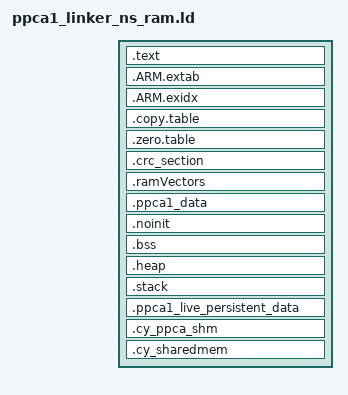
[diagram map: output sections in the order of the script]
/***************************************************************************//**
* \file psc3_p8_ppca1_ns_ram.ld
* \version 1.0.0
*
* Linker file for the GNU C compiler.
*
* The main purpose of the linker script is to describe how the sections in the
* input files should be mapped into the output file, and to control the memory
* layout of the output file.
*
* \note The entry point location is fixed and starts at 0x10000000. The valid
* application image should be placed there.
*
* \note The linker files included with the PDL template projects must be generic
* and handle all common use cases. Your project may not use every section
* defined in the linker files. In that case you may see warnings during the
* build process. In your project, you can simply comment out or remove the
* relevant code in the linker file.
*
********************************************************************************
* \copyright
* Copyright 2024 Cypress Semiconductor Corporation
* SPDX-License-Identifier: Apache-2.0
*
* Licensed under the Apache License, Version 2.0 (the "License");
* you may not use this file except in compliance with the License.
* You may obtain a copy of the License at
*
*     http://www.apache.org/licenses/LICENSE-2.0
*
* Unless required by applicable law or agreed to in writing, software
* distributed under the License is distributed on an "AS IS" BASIS,
* WITHOUT WARRANTIES OR CONDITIONS OF ANY KIND, either express or implied.
* See the License for the specific language governing permissions and
* limitations under the License.
*******************************************************************************/

OUTPUT_FORMAT ("elf32-littlearm", "elf32-bigarm", "elf32-littlearm")
SEARCH_DIR(.)
GROUP(-lgcc -lc -lnosys )
GROUP(libgcc.a libc.a libm.a libnosys.a)
ENTRY(Reset_Handler)

/* The size of the stack section at the end of CM33 SRAM */
RAMVECTORS_ALIGNMENT        = 512;
STACK_SIZE = 0x800; /* 2K for stack */


/* Force symbol to be entered in the output file as an undefined symbol. Doing
* this may, for example, trigger linking of additional modules from standard
* libraries. You may list several symbols for each EXTERN, and you may use
* EXTERN multiple times. This command has the same effect as the -u command-line
* option.
*/
EXTERN(Reset_Handler)

/* Include the device memory definitions generated by the Device Configurator */
INCLUDE cymem_gnu_CM33_2.ld

/* Select active PPCA1 slot using BUILD_NUM parity.
 * Even BUILD_NUM -> slot A, odd BUILD_NUM -> slot B.
 */
BUILD_NUM = DEFINED(BUILD_NUM) ? BUILD_NUM : 0;
ppca1_code_start = ((BUILD_NUM % 2) == 0) ? ORIGIN(ppca1_code_A) : ORIGIN(ppca1_code_B);
ppca1_crc_start  = ((BUILD_NUM % 2) == 0) ? ORIGIN(ppca1_crc_A) : ORIGIN(ppca1_crc_B);
ppca1_code_size  = ((BUILD_NUM % 2) == 0) ? LENGTH(ppca1_code_A) : LENGTH(ppca1_code_B);
ppca1_crc_size   = ((BUILD_NUM % 2) == 0) ? LENGTH(ppca1_crc_A) : LENGTH(ppca1_crc_B);

/* Library configurations */
GROUP(libgcc.a libc.a libm.a libnosys.a)

/* Linker script to place sections and symbol values. Should be used together
 * with other linker script that defines memory regions FLASH and RAM.
 * It references following symbols, which must be defined in code:
 *   Reset_Handler : Entry of reset handler
 *
 * It defines following symbols, which code can use without definition:
 *   __exidx_start
 *   __exidx_end
 *   __copy_table_start__
 *   __copy_table_end__
 *   __zero_table_start__
 *   __zero_table_end__
 *   __etext
 *   __data_start__
 *   __preinit_array_start
 *   __preinit_array_end
 *   __init_array_start
 *   __init_array_end
 *   __fini_array_start
 *   __fini_array_end
 *   __data_end__
 *   __bss_start__
 *   __bss_end__
 *   __end__
 *   end
 *   __HeapLimit
 *   __StackLimit
 *   __StackTop
 *   __stack
 *   __Vectors_End
 *   __Vectors_Size
 */


SECTIONS
{
    /* Cortex-M33 application flash area */
    .text ppca1_code_start : AT(ppca1_code_start)
    {
        /* Cortex-M33 flash vector table */
        . = ALIGN(4);
        __Vectors = . ;
        KEEP(*(.vectors))
        . = ALIGN(4);
        __Vectors_End = .;
        __Vectors_Size = __Vectors_End - __Vectors;
        __end__ = .;

        . = ALIGN(4);
        *(.text*)

        KEEP(*(.init))
        KEEP(*(.fini))

        /* .ctors */
        *crtbegin.o(.ctors)
        *crtbegin?.o(.ctors)
        *(EXCLUDE_FILE(*crtend?.o *crtend.o) .ctors)
        *(SORT(.ctors.*))
        *(.ctors)

        /* .dtors */
        *crtbegin.o(.dtors)
        *crtbegin?.o(.dtors)
        *(EXCLUDE_FILE(*crtend?.o *crtend.o) .dtors)
        *(SORT(.dtors.*))
        *(.dtors)

        /* Read-only code (constants). */
        *(.rodata .rodata.* .constdata .constdata.* .conststring .conststring.*)

        KEEP(*(.eh_frame*))
    }


    .ARM.extab :
    {
        *(.ARM.extab* .gnu.linkonce.armextab.*)
    }

    __exidx_start = .;

    .ARM.exidx :
    {
        *(.ARM.exidx* .gnu.linkonce.armexidx.*)
    }
    __exidx_end = .;


    /* copy code-RAM to data-RAM */
    .copy.table :
    {
        . = ALIGN(4);
        __copy_table_start__ = .;

        /* Note: The interrupt vector table is NOT copied to data SRAM.
         * For PPCA cores the application executes directly from code SRAM,
         * so the vector table is used in-place at the image base. This avoids
         * the vector copy on every (cold and live) boot and keeps the live
         * update app switch fast. The VTOR is set to the image base directly. */

        /* Copy data section from code-RAM to data-RAM */
        LONG (__etext)                                      /* From */
        LONG (__data_start__)                               /* To   */
        LONG ((__data_end__ - __data_start__)/4)            /* Size */

        __copy_table_end__ = .;
    }


    /* Mark bss sections */
    .zero.table :
    {
        . = ALIGN(4);
        __zero_table_start__ = .;
        LONG (__bss_start__)
        LONG ((__bss_end__ - __bss_start__)/4)
        __zero_table_end__ = .;
    }

    __etext =  . ;

    ASSERT(__etext <= (ppca1_code_start + ppca1_code_size), "region ppca1_code overflowed")

    /* Define symbols for the start and end of the CRC calculation range */
    __crc_start__ = ppca1_code_start;
    __crc_end__   = ppca1_crc_start;
    
    .crc_section ppca1_crc_start :
    {
        . = ALIGN(4);
        KEEP(*(.crc_section))
    }

    .ramVectors (NOLOAD) : /*ALIGN(8)*/
    {
        . = ALIGN(RAMVECTORS_ALIGNMENT);
        __ram_vectors_start__ = .;
        KEEP(*(.ram_vectors))
        __ram_vectors_end__   = .;
    } > ppca1_data

    .ppca1_data : AT (__etext)
    {
        __data_start__ = .;

        . = ALIGN(4);
        *(.data*)

        . = ALIGN(4);
        /* preinit data */
        PROVIDE_HIDDEN (__preinit_array_start = .);
        KEEP(*(.preinit_array))
        PROVIDE_HIDDEN (__preinit_array_end = .);

        . = ALIGN(4);
        /* init data */
        PROVIDE_HIDDEN (__init_array_start = .);
        KEEP(*(SORT(.init_array.*)))
        KEEP(*(.init_array))
        PROVIDE_HIDDEN (__init_array_end = .);

        . = ALIGN(4);
        /* finit data */
        PROVIDE_HIDDEN (__fini_array_start = .);
        KEEP(*(SORT(.fini_array.*)))
        KEEP(*(.fini_array))
        PROVIDE_HIDDEN (__fini_array_end = .);

        KEEP(*(.jcr*))
        . = ALIGN(4);

        __data_end__ = .;

    } > ppca1_data


    /* Place variables in the section that should not be initialized during the
    *  device startup.
    */
    .noinit (NOLOAD) : ALIGN(8)
    {
      KEEP(*(.noinit))
    } > ppca1_data


    /* The uninitialized global or static variables are placed in this section.
    *
    * The NOLOAD attribute tells linker that .bss section does not consume
    * any space in the image. The NOLOAD attribute changes the .bss type to
    * NOBITS, and that  makes linker to A) not allocate section in memory, and
    * A) put information to clear the section with all zeros during application
    * loading.
    *
    * Without the NOLOAD attribute, the .bss section might get PROGBITS type.
    * This  makes linker to A) allocate zeroed section in memory, and B) copy
    * this section to RAM during application loading.
    */
    .bss (NOLOAD):
    {
        . = ALIGN(4);
        __bss_start__ = .;
        *(.bss*)
        *(COMMON)
        . = ALIGN(4);
        __bss_end__ = .;
    } > ppca1_data


    .heap (NOLOAD):
    {
        . = ALIGN(8);
        __HeapBase = .;
        __end__ = .;
        end = __end__;
        KEEP(*(.heap*))
        . = ALIGN(8);
        . = ORIGIN(ppca1_data) + LENGTH(ppca1_data) - STACK_SIZE;
        __HeapLimit = .;
    } > ppca1_data


    .stack (NOLOAD):
    {
        KEEP(*(.stack*))
        . = . + STACK_SIZE;      
    } > ppca1_data


    /* Live update persistent data - not cleared by .bss/.data init during startup.
     * Variables placed in this region survive firmware updates.
     * Use __attribute__((section(".cy_live_persistent_data"))) to place data here.
     */
    .ppca1_live_persistent_data (NOLOAD) : ALIGN(4)
    {
        . = ALIGN(4);
        __live_persistent_data_start__ = .;
        KEEP(*(.cy_live_persistent_data))
        . = ALIGN(4);
        __live_persistent_data_end__ = .;
    } > ppca1_live_persistent_data


    .cy_ppca_shm (NOLOAD) : ALIGN (4)
    {
        . = ALIGN(4);
        __ppca_sharedmem_start__ = .;
        KEEP(*(SORT_NONE(.cy_ppca_shm)))
        KEEP(*(SORT_NONE(.cy_ppca_shm.lib)))
        . = ALIGN(4);
        __ppca_sharedmem_end__ = .;
    } > ppca_shm_data

    .cy_sharedmem (NOLOAD): ALIGN (4)
    {
        . = ALIGN(4);
        __cy_sharedmem_start__ = .;
        KEEP(*(.cy_sharedmem))
        . = ALIGN(4);
        __cy_sharedmem_end__ = .;
    } > ppca_shm_data

    /* Set stack top to end of RAM, and stack limit move down by
     * size of stack_dummy section */
    . = ALIGN(32);
    __StackTop = ORIGIN(ppca1_data) + LENGTH(ppca1_data);
    __StackLimit = __StackTop - STACK_SIZE;
    PROVIDE(__stack = __StackTop);

    /* Check if data + heap + stack exceeds RAM limit */
    ASSERT(__StackLimit >= __HeapLimit, "region RAM overflowed with stack")

}


/* EOF */
